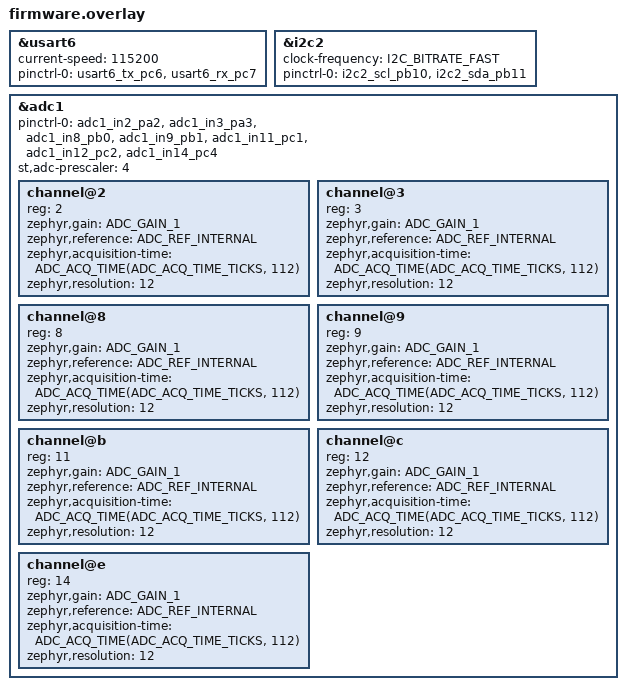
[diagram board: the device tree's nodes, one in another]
&usart6 {
    current-speed = <115200>;
    pinctrl-0 = <&usart6_tx_pc6 &usart6_rx_pc7>;
    pinctrl-names = "default";
    status = "okay";
};

&i2c2 {
    clock-frequency = <I2C_BITRATE_FAST>;
    pinctrl-0 = <&i2c2_scl_pb10 &i2c2_sda_pb11>;
    pinctrl-names = "default";
    status = "okay";
};

&adc1 {
    pinctrl-0 = <&adc1_in2_pa2
                 &adc1_in3_pa3
                 &adc1_in8_pb0
                 &adc1_in9_pb1
                 &adc1_in11_pc1
                 &adc1_in12_pc2
                 &adc1_in14_pc4>;
    pinctrl-names = "default";
    st,adc-prescaler = <4>;
    status = "okay";

    #address-cells = <1>;
    #size-cells = <0>;

    channel@2 {
        reg = <2>;
        zephyr,gain = "ADC_GAIN_1";
        zephyr,reference = "ADC_REF_INTERNAL";
        zephyr,acquisition-time = <ADC_ACQ_TIME(ADC_ACQ_TIME_TICKS, 112)>;
        zephyr,resolution = <12>;
    };

    channel@3 {
        reg = <3>;
        zephyr,gain = "ADC_GAIN_1";
        zephyr,reference = "ADC_REF_INTERNAL";
        zephyr,acquisition-time = <ADC_ACQ_TIME(ADC_ACQ_TIME_TICKS, 112)>;
        zephyr,resolution = <12>;
    };

    channel@8 {
        reg = <8>;
        zephyr,gain = "ADC_GAIN_1";
        zephyr,reference = "ADC_REF_INTERNAL";
        zephyr,acquisition-time = <ADC_ACQ_TIME(ADC_ACQ_TIME_TICKS, 112)>;
        zephyr,resolution = <12>;
    };

    channel@9 {
        reg = <9>;
        zephyr,gain = "ADC_GAIN_1";
        zephyr,reference = "ADC_REF_INTERNAL";
        zephyr,acquisition-time = <ADC_ACQ_TIME(ADC_ACQ_TIME_TICKS, 112)>;
        zephyr,resolution = <12>;
    };

    channel@b {
        reg = <11>;
        zephyr,gain = "ADC_GAIN_1";
        zephyr,reference = "ADC_REF_INTERNAL";
        zephyr,acquisition-time = <ADC_ACQ_TIME(ADC_ACQ_TIME_TICKS, 112)>;
        zephyr,resolution = <12>;
    };

    channel@c {
        reg = <12>;
        zephyr,gain = "ADC_GAIN_1";
        zephyr,reference = "ADC_REF_INTERNAL";
        zephyr,acquisition-time = <ADC_ACQ_TIME(ADC_ACQ_TIME_TICKS, 112)>;
        zephyr,resolution = <12>;
    };

    channel@e {
        reg = <14>;
        zephyr,gain = "ADC_GAIN_1";
        zephyr,reference = "ADC_REF_INTERNAL";
        zephyr,acquisition-time = <ADC_ACQ_TIME(ADC_ACQ_TIME_TICKS, 112)>;
        zephyr,resolution = <12>;
    };
};
